# STM32U5A5 register map
File version: 0.2
CPU: CM33 r0p1, little endian, MPU, FPU, 4 interrupt priority bits
Registers are 32-bit, read-write, reset 0x0 unless marked. A register's access mark holds for its fields unless they carry their own. Offsets are from the block's base; [hi:lo] are bit positions; {n}, {i} and the like mark numbered series.

## DCMI — Digital camera interface
Base 0x4202C000
Same registers: SEC_DCMI 0x5202C000
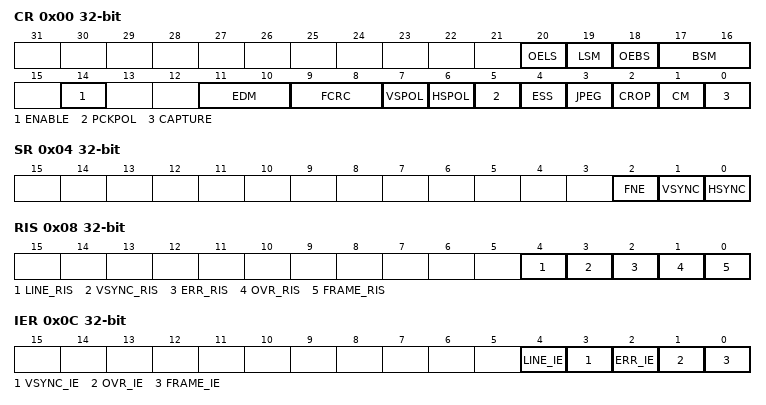
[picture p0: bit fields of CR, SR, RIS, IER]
0x00 CR — control register
  [20] OELS — Odd/Even Line Select (Line Select Start)
  [19] LSM — Line Select mode
  [18] OEBS — Odd/Even Byte Select (Byte Select Start)
  [17:16] BSM — Byte Select mode
  [14] ENABLE — DCMI enable
  [11:10] EDM — Extended data mode
  [9:8] FCRC — Frame capture rate control
  [7] VSPOL — Vertical synchronization polarity
  [6] HSPOL — Horizontal synchronization polarity
  [5] PCKPOL — Pixel clock polarity
  [4] ESS — Embedded synchronization select
  [3] JPEG — JPEG format
  [2] CROP — Crop feature
  [1] CM — Capture mode
  [0] CAPTURE — Capture enable
0x04 SR ro — status register
  [2] FNE — FIFO not empty
  [1] VSYNC — Vertical synchronization
  [0] HSYNC — Horizontal synchronization
0x08 RIS ro — raw interrupt status register
  [4] LINE_RIS — Line raw interrupt status
  [3] VSYNC_RIS — DCMI_VSYNC raw interrupt status
  [2] ERR_RIS — Synchronization error raw interrupt status
  [1] OVR_RIS — Overrun raw interrupt status
  [0] FRAME_RIS — Capture complete raw interrupt status
0x0C IER — interrupt enable register
  [4] LINE_IE — Line interrupt enable
  [3] VSYNC_IE — DCMI_VSYNC interrupt enable
  [2] ERR_IE — Synchronization error interrupt enable
  [1] OVR_IE — Overrun interrupt enable
  [0] FRAME_IE — Capture complete interrupt enable
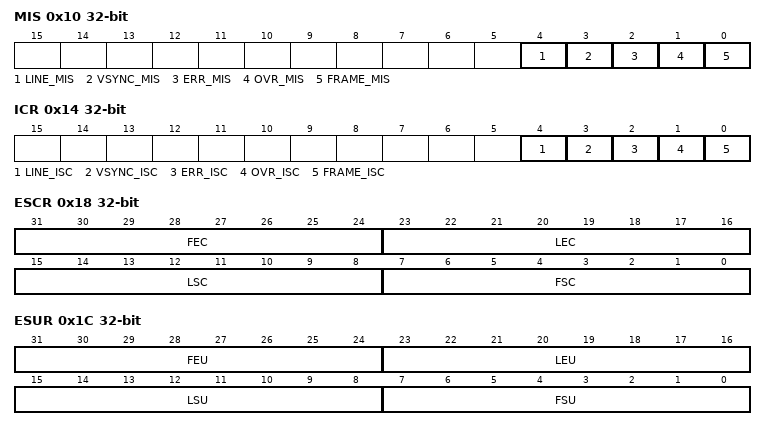
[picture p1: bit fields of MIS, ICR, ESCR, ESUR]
0x10 MIS ro — masked interrupt status register
  [4] LINE_MIS — Line masked interrupt status
  [3] VSYNC_MIS — VSYNC masked interrupt status
  [2] ERR_MIS — Synchronization error masked interrupt status
  [1] OVR_MIS — Overrun masked interrupt status
  [0] FRAME_MIS — Capture complete masked interrupt status
0x14 ICR wo — interrupt clear register
  [4] LINE_ISC — line interrupt status clear
  [3] VSYNC_ISC — Vertical Synchronization interrupt status clear
  [2] ERR_ISC — Synchronization error interrupt status clear
  [1] OVR_ISC — Overrun interrupt status clear
  [0] FRAME_ISC — Capture complete interrupt status clear
0x18 ESCR — background offset register
  [31:24] FEC — Frame end delimiter code
  [23:16] LEC — Line end delimiter code
  [15:8] LSC — Line start delimiter code
  [7:0] FSC — Frame start delimiter code
0x1C ESUR — embedded synchronization unmask register
  [31:24] FEU — Frame end delimiter unmask
  [23:16] LEU — Line end delimiter unmask
  [15:8] LSU — Line start delimiter unmask
  [7:0] FSU — Frame start delimiter unmask
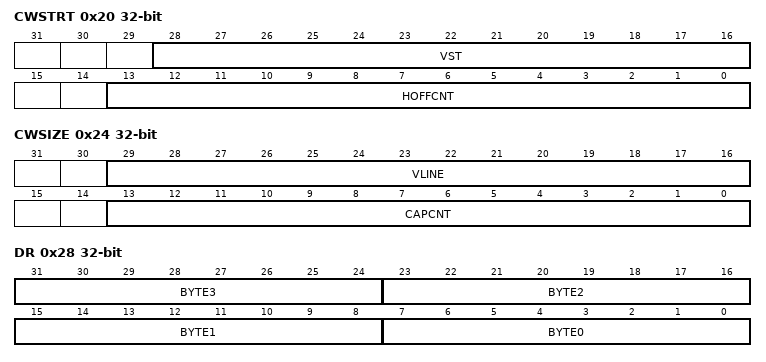
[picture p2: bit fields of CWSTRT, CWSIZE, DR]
0x20 CWSTRT — crop window start
  [28:16] VST — Vertical start line count
  [13:0] HOFFCNT — Horizontal offset count
0x24 CWSIZE — crop window size
  [29:16] VLINE — Vertical line count
  [13:0] CAPCNT — Capture count
0x28 DR ro — data register
  [8n+7:8n] BYTE{n} (n=0..3) — Data byte {n}

## DLYBOS1 — The delay block (DLYB) is used to generate an output clock that is dephased from the input clock
Base 0x420CF000
Same registers: DLYBSD1 0x420C8400, DLYBSD2 0x420C8800, DLYBOS2 0x420CF400, SEC_DLYBSD1 0x520C8400, SEC_DLYBSD2 0x520C8800, SEC_DLYBOS1 0x520CF000, SEC_DLYBOS2 0x520CF400
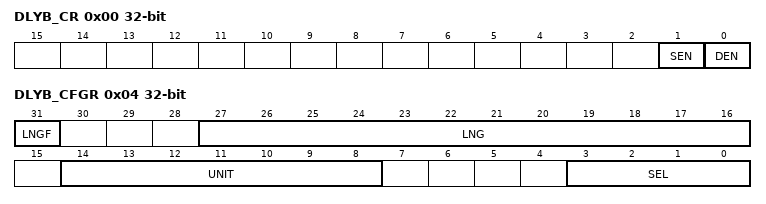
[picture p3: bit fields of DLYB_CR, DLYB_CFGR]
0x00 DLYB_CR — control register
  [1] SEN — OPALPM
  [0] DEN — Operational amplifier Enable
0x04 DLYB_CFGR access per field — configuration register
  [31] LNGF ro, [27:16] LNG ro, [14:8] UNIT rw, [3:0] SEL rw

## EXTI — External interrupt/event controller
Base 0x46022000
Same registers: SEC_EXTI 0x56022000
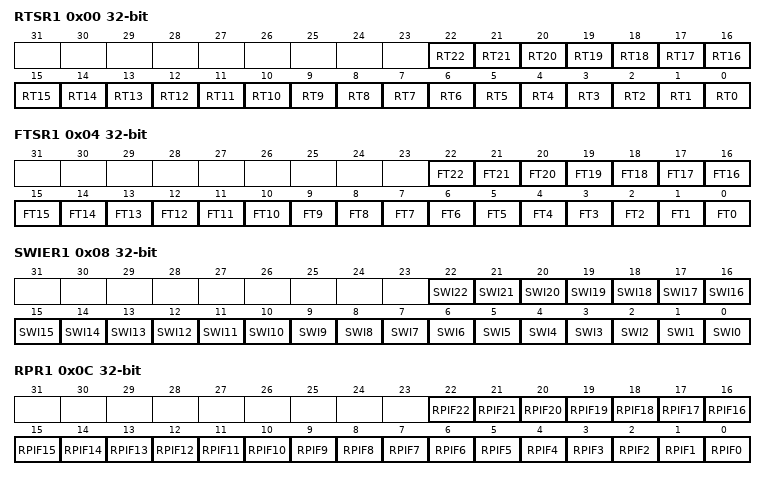
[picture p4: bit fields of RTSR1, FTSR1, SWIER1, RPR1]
0x00 RTSR1 — EXTI rising trigger selection register
  [n] RT{n} (n=0..22) — Rising trigger event configuration bit of configurable event input x
0x04 FTSR1 — EXTI falling trigger selection register
  [n] FT{n} (n=0..22) — Falling trigger event configuration bit of configurable event input x
0x08 SWIER1 — EXTI software interrupt event register
  [n] SWI{n} (n=0..22) — Software interrupt on event x
0x0C RPR1 — EXTI rising edge pending register
  [n] RPIF{n} (n=0..22) — configurable event inputs x rising edge pending bit
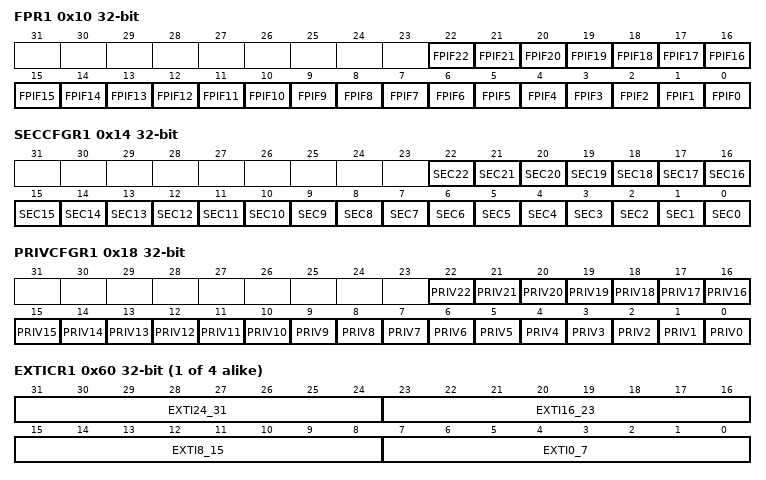
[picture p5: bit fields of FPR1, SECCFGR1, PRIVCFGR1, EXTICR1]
0x10 FPR1 — EXTI falling edge pending register
  [n] FPIF{n} (n=0..22) — configurable event inputs x falling edge pending bit.
0x14 SECCFGR1 — EXTI security configuration register
  [n] SEC{n} (n=0..22) — Security enable on event input x
0x18 PRIVCFGR1 — EXTI privilege configuration register
  [n] PRIV{n} (n=0..22) — Security enable on event input x
{0x5C+4i} EXTICR{i} (i=1..4) — EXTI external interrupt selection register
  [31:24] EXTI24_31 — EXTIm+3 GPIO port selection
  [23:16] EXTI16_23 — EXTIm+2 GPIO port selection
  [15:8] EXTI8_15 — EXTIm+1 GPIO port selection
  [7:0] EXTI0_7 — EXTIm GPIO port selection
0x70 LOCKR — EXTI lock register
  [0] LOCK
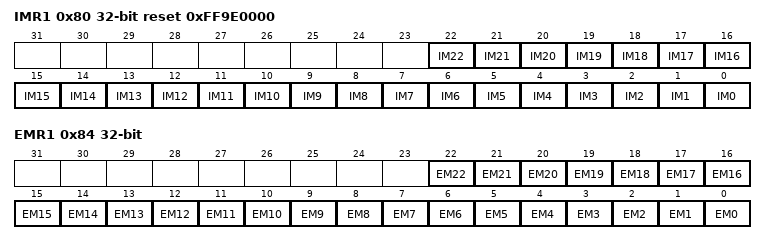
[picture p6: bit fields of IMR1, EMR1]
0x80 IMR1 reset 0xFF9E0000 — EXTI CPU wakeup with interrupt mask register
  [n] IM{n} (n=0..22) — CPU wakeup with interrupt mask on event input
0x84 EMR1 — EXTI CPU wakeup with event mask register
  [n] EM{n} (n=0..22) — CPU wakeup with event generation mask on event input
